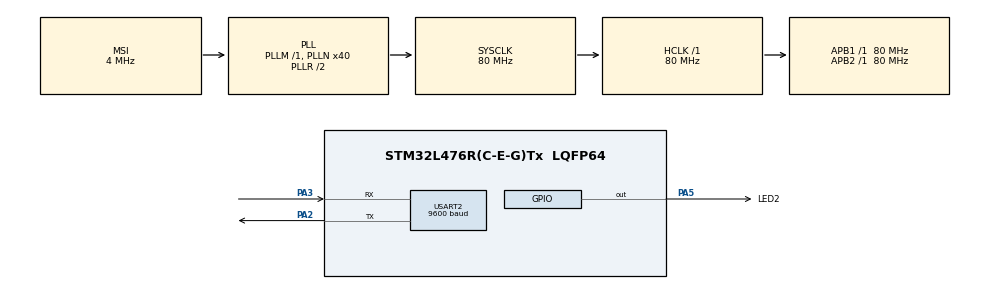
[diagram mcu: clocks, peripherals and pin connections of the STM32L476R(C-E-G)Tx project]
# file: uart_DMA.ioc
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Dma.Request0=USART2_RX
Dma.USART2_RX.0.Direction=DMA_PERIPH_TO_MEMORY
Dma.USART2_RX.0.Instance=DMA1_Channel6
Dma.USART2_RX.0.MemDataAlignment=DMA_MDATAALIGN_BYTE
Dma.USART2_RX.0.MemInc=DMA_MINC_ENABLE
Dma.USART2_RX.0.Mode=DMA_CIRCULAR
Dma.USART2_RX.0.PeriphDataAlignment=DMA_PDATAALIGN_BYTE
Dma.USART2_RX.0.PeriphInc=DMA_PINC_DISABLE
Dma.USART2_RX.0.Priority=DMA_PRIORITY_LOW
Mcu.Family=STM32L4
Mcu.Name=STM32L476R(C-E-G)Tx
Mcu.Package=LQFP64
NVIC.DMA1_Channel6_IRQn=true\:0\:0\:false\:true\:true\:1\:false
NVIC.PriorityGroup=NVIC_PRIORITYGROUP_4
NVIC.USART2_IRQn=true\:0\:0\:false\:false\:true\:true
PA13\ (JTMS-SWDIO).Mode=Serial_Wire
PA13\ (JTMS-SWDIO).Signal=SYS_JTMS-SWDIO
PA14\ (JTCK-SWCLK).Mode=Serial_Wire
PA14\ (JTCK-SWCLK).Signal=SYS_JTCK-SWCLK
PA2.Mode=Asynchronous
PA2.Signal=USART2_TX
PA3.Mode=Asynchronous
PA3.Signal=USART2_RX
PA5.GPIO_Label=LED2
PA5.Signal=GPIO_Output
ProjectManager.HeapSize=0x200
ProjectManager.StackSize=0x400
ProjectManager.TargetToolchain=SW4STM32
RCC.AHBFreq_Value=80000000
RCC.APB1Freq_Value=80000000
RCC.APB1TimFreq_Value=80000000
RCC.APB2Freq_Value=80000000
RCC.APB2TimFreq_Value=80000000
RCC.CortexFreq_Value=80000000
RCC.HCLKFreq_Value=80000000
RCC.HSE_VALUE=8000000
RCC.HSI_VALUE=16000000
RCC.LSE_VALUE=32768
RCC.MSI_VALUE=4000000
RCC.PLLN=40
RCC.SYSCLKFreq_VALUE=80000000
RCC.SYSCLKSource=RCC_SYSCLKSOURCE_PLLCLK
RCC.VCOOutputFreq_Value=160000000
USART2.BaudRate=9600
USART2.VirtualMode-Asynchronous=VM_ASYNC
USART2.WordLength=WORDLENGTH_8B
board=uart_DMA

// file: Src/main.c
/**
  ******************************************************************************
  * @file           : main.c
  * @brief          : Main program body
  ******************************************************************************
  ** This notice applies to any and all portions of this file
  * that are not between comment pairs USER CODE BEGIN and
  * USER CODE END. Other portions of this file, whether
  * inserted by the user or by software development tools
  * are owned by their respective copyright owners.
  *
  * COPYRIGHT(c) 2018 STMicroelectronics
  *
  * Redistribution and use in source and binary forms, with or without modification,
  * are permitted provided that the following conditions are met:
  *   1. Redistributions of source code must retain the above copyright notice,
  *      this list of conditions and the following disclaimer.
  *   2. Redistributions in binary form must reproduce the above copyright notice,
  *      this list of conditions and the following disclaimer in the documentation
  *      and/or other materials provided with the distribution.
  *   3. Neither the name of STMicroelectronics nor the names of its contributors
  *      may be used to endorse or promote products derived from this software
  *      without specific prior written permission.
  *
  * THIS SOFTWARE IS PROVIDED BY THE COPYRIGHT HOLDERS AND CONTRIBUTORS "AS IS"
  * AND ANY EXPRESS OR IMPLIED WARRANTIES, INCLUDING, BUT NOT LIMITED TO, THE
  * IMPLIED WARRANTIES OF MERCHANTABILITY AND FITNESS FOR A PARTICULAR PURPOSE ARE
  * DISCLAIMED. IN NO EVENT SHALL THE COPYRIGHT HOLDER OR CONTRIBUTORS BE LIABLE
  * FOR ANY DIRECT, INDIRECT, INCIDENTAL, SPECIAL, EXEMPLARY, OR CONSEQUENTIAL
  * DAMAGES (INCLUDING, BUT NOT LIMITED TO, PROCUREMENT OF SUBSTITUTE GOODS OR
  * SERVICES; LOSS OF USE, DATA, OR PROFITS; OR BUSINESS INTERRUPTION) HOWEVER
  * CAUSED AND ON ANY THEORY OF LIABILITY, WHETHER IN CONTRACT, STRICT LIABILITY,
  * OR TORT (INCLUDING NEGLIGENCE OR OTHERWISE) ARISING IN ANY WAY OUT OF THE USE
  * OF THIS SOFTWARE, EVEN IF ADVISED OF THE POSSIBILITY OF SUCH DAMAGE.
  *
  ******************************************************************************
  */
#include "main.h"
#include "stm32l4xx_hal.h"

/* USER CODE BEGIN Includes */
#define MAXCLISTRING 100

/* USER CODE END Includes */

UART_HandleTypeDef huart2;
DMA_HandleTypeDef hdma_usart2_rx;

/* USER CODE BEGIN PV */
/* Private variables ---------------------------------------------------------*/
uint32_t rxBuff = '\000';
uint8_t rxString[100]; // where we build string from incoming characters
int rxindex = 0;

/* USER CODE END PV */

void SystemClock_Config(void);
static void MX_GPIO_Init(void);
static void MX_DMA_Init(void);
static void MX_USART2_UART_Init(void);
static void MX_NVIC_Init(void);

/* USER CODE BEGIN PFP */
/* Private function prototypes -----------------------------------------------*/

/* USER CODE END PFP */

int main(void)
{

  /* MCU Configuration----------------------------------------------------------*/

  /* Reset of all peripherals, Initializes the Flash interface and the Systick. */
  HAL_Init();

  /* Configure the system clock */
  SystemClock_Config();

  /* Initialize all configured peripherals */
  MX_GPIO_Init();
  MX_DMA_Init();
  MX_USART2_UART_Init();

  /* Initialize interrupts */
  MX_NVIC_Init();
  /* USER CODE BEGIN 2 */
  __HAL_UART_FLUSH_DRREGISTER(&huart2);
  HAL_UART_Receive_DMA(&huart2,&rxBuff,1);

  /* USER CODE END 2 */

  /* Infinite loop */
  while (1)
  {

  }

}

void SystemClock_Config(void)
{

  RCC_OscInitTypeDef RCC_OscInitStruct;
  RCC_ClkInitTypeDef RCC_ClkInitStruct;
  RCC_PeriphCLKInitTypeDef PeriphClkInit;

    /**Initializes the CPU, AHB and APB busses clocks
    */
  RCC_OscInitStruct.OscillatorType = RCC_OSCILLATORTYPE_MSI;
  RCC_OscInitStruct.MSIState = RCC_MSI_ON;
  RCC_OscInitStruct.MSICalibrationValue = 0;
  RCC_OscInitStruct.MSIClockRange = RCC_MSIRANGE_6;
  RCC_OscInitStruct.PLL.PLLState = RCC_PLL_ON;
  RCC_OscInitStruct.PLL.PLLSource = RCC_PLLSOURCE_MSI;
  RCC_OscInitStruct.PLL.PLLM = 1;
  RCC_OscInitStruct.PLL.PLLN = 40;
  RCC_OscInitStruct.PLL.PLLP = RCC_PLLP_DIV7;
  RCC_OscInitStruct.PLL.PLLQ = RCC_PLLQ_DIV2;
  RCC_OscInitStruct.PLL.PLLR = RCC_PLLR_DIV2;
  if (HAL_RCC_OscConfig(&RCC_OscInitStruct) != HAL_OK)
  {
    _Error_Handler(__FILE__, __LINE__);
  }

    /**Initializes the CPU, AHB and APB busses clocks
    */
  RCC_ClkInitStruct.ClockType = RCC_CLOCKTYPE_HCLK|RCC_CLOCKTYPE_SYSCLK
                              |RCC_CLOCKTYPE_PCLK1|RCC_CLOCKTYPE_PCLK2;
  RCC_ClkInitStruct.SYSCLKSource = RCC_SYSCLKSOURCE_PLLCLK;
  RCC_ClkInitStruct.AHBCLKDivider = RCC_SYSCLK_DIV1;
  RCC_ClkInitStruct.APB1CLKDivider = RCC_HCLK_DIV1;
  RCC_ClkInitStruct.APB2CLKDivider = RCC_HCLK_DIV1;

  if (HAL_RCC_ClockConfig(&RCC_ClkInitStruct, FLASH_LATENCY_4) != HAL_OK)
  {
    _Error_Handler(__FILE__, __LINE__);
  }

  PeriphClkInit.PeriphClockSelection = RCC_PERIPHCLK_USART2;
  PeriphClkInit.Usart2ClockSelection = RCC_USART2CLKSOURCE_PCLK1;
  if (HAL_RCCEx_PeriphCLKConfig(&PeriphClkInit) != HAL_OK)
  {
    _Error_Handler(__FILE__, __LINE__);
  }

    /**Configure the main internal regulator output voltage
    */
  if (HAL_PWREx_ControlVoltageScaling(PWR_REGULATOR_VOLTAGE_SCALE1) != HAL_OK)
  {
    _Error_Handler(__FILE__, __LINE__);
  }

    /**Configure the Systick interrupt time
    */
  HAL_SYSTICK_Config(HAL_RCC_GetHCLKFreq()/1000);

    /**Configure the Systick
    */
  HAL_SYSTICK_CLKSourceConfig(SYSTICK_CLKSOURCE_HCLK);

  /* SysTick_IRQn interrupt configuration */
  HAL_NVIC_SetPriority(SysTick_IRQn, 0, 0);
}

/**
  * @brief NVIC Configuration.
  * @retval None
  */
static void MX_NVIC_Init(void)
{
  /* DMA1_Channel6_IRQn interrupt configuration */
  HAL_NVIC_SetPriority(DMA1_Channel6_IRQn, 0, 0);
  HAL_NVIC_EnableIRQ(DMA1_Channel6_IRQn);
}

/* USART2 init function */
static void MX_USART2_UART_Init(void)
{

  huart2.Instance = USART2;
  huart2.Init.BaudRate = 9600;
  huart2.Init.WordLength = UART_WORDLENGTH_8B;
  huart2.Init.StopBits = UART_STOPBITS_1;
  huart2.Init.Parity = UART_PARITY_NONE;
  huart2.Init.Mode = UART_MODE_TX_RX;
  huart2.Init.HwFlowCtl = UART_HWCONTROL_NONE;
  huart2.Init.OverSampling = UART_OVERSAMPLING_16;
  huart2.Init.OneBitSampling = UART_ONE_BIT_SAMPLE_DISABLE;
  huart2.AdvancedInit.AdvFeatureInit = UART_ADVFEATURE_NO_INIT;
  if (HAL_UART_Init(&huart2) != HAL_OK)
  {
    _Error_Handler(__FILE__, __LINE__);
  }

}

static void MX_DMA_Init(void)
{
  /* DMA controller clock enable */
  __HAL_RCC_DMA1_CLK_ENABLE();

}

/** Configure pins as
        * Analog
        * Input
        * Output
        * EVENT_OUT
        * EXTI
*/
static void MX_GPIO_Init(void)
{

  GPIO_InitTypeDef GPIO_InitStruct;

  /* GPIO Ports Clock Enable */
  __HAL_RCC_GPIOA_CLK_ENABLE();

  /*Configure GPIO pin Output Level */
  HAL_GPIO_WritePin(LED2_GPIO_Port, LED2_Pin, GPIO_PIN_RESET);

  /*Configure GPIO pin : LED2_Pin */
  GPIO_InitStruct.Pin = LED2_Pin;
  GPIO_InitStruct.Mode = GPIO_MODE_OUTPUT_PP;
  GPIO_InitStruct.Pull = GPIO_NOPULL;
  GPIO_InitStruct.Speed = GPIO_SPEED_FREQ_LOW;
  HAL_GPIO_Init(LED2_GPIO_Port, &GPIO_InitStruct);

}

/* USER CODE BEGIN 4 */
 void HAL_UART_RxCpltCallback(UART_HandleTypeDef *huart){
	  __HAL_UART_FLUSH_DRREGISTER(&huart2); // Clear the buffer to prevent overrun

	    int i = 0;

	   //print(&rxBuffer); // Echo the character that caused this callback so the user can see what they are typing

	    if (rxBuff == 8 || rxBuff == 127) // If Backspace or del
	    {
	       // print(" \b"); // "\b space \b" clears the terminal character. Remember we just echoced a \b so don't need another one here, just space and \b
	        rxindex--;
	        if (rxindex < 0) rxindex = 0;
	    }

	    else if (rxBuff == '\n' || rxBuff == '\r') // If Enter
	    {
	        //executeSerialCommand(rxString);
	        rxString[rxindex] = 0;
	        rxindex = 0;
	        for (i = 0; i < MAXCLISTRING; i++) rxString[i] = 0; // Clear the string buffer
	    }

	    else
	    {
	        rxString[rxindex] = rxBuff; // Add that character to the string
	        rxindex++;
	        if (rxindex > MAXCLISTRING) // User typing too much, we can't have commands that big
	        {
	            rxindex = 0;
	            for (i = 0; i < MAXCLISTRING; i++) rxString[i] = 0; // Clear the string buffer
	            //print("\r\nConsole> ");
	        }
	    }
 }

/* USER CODE END 4 */

void _Error_Handler(char *file, int line)
{
  while(1)
  {
  }
}

/************************ (C) COPYRIGHT STMicroelectronics *****END OF FILE****/
